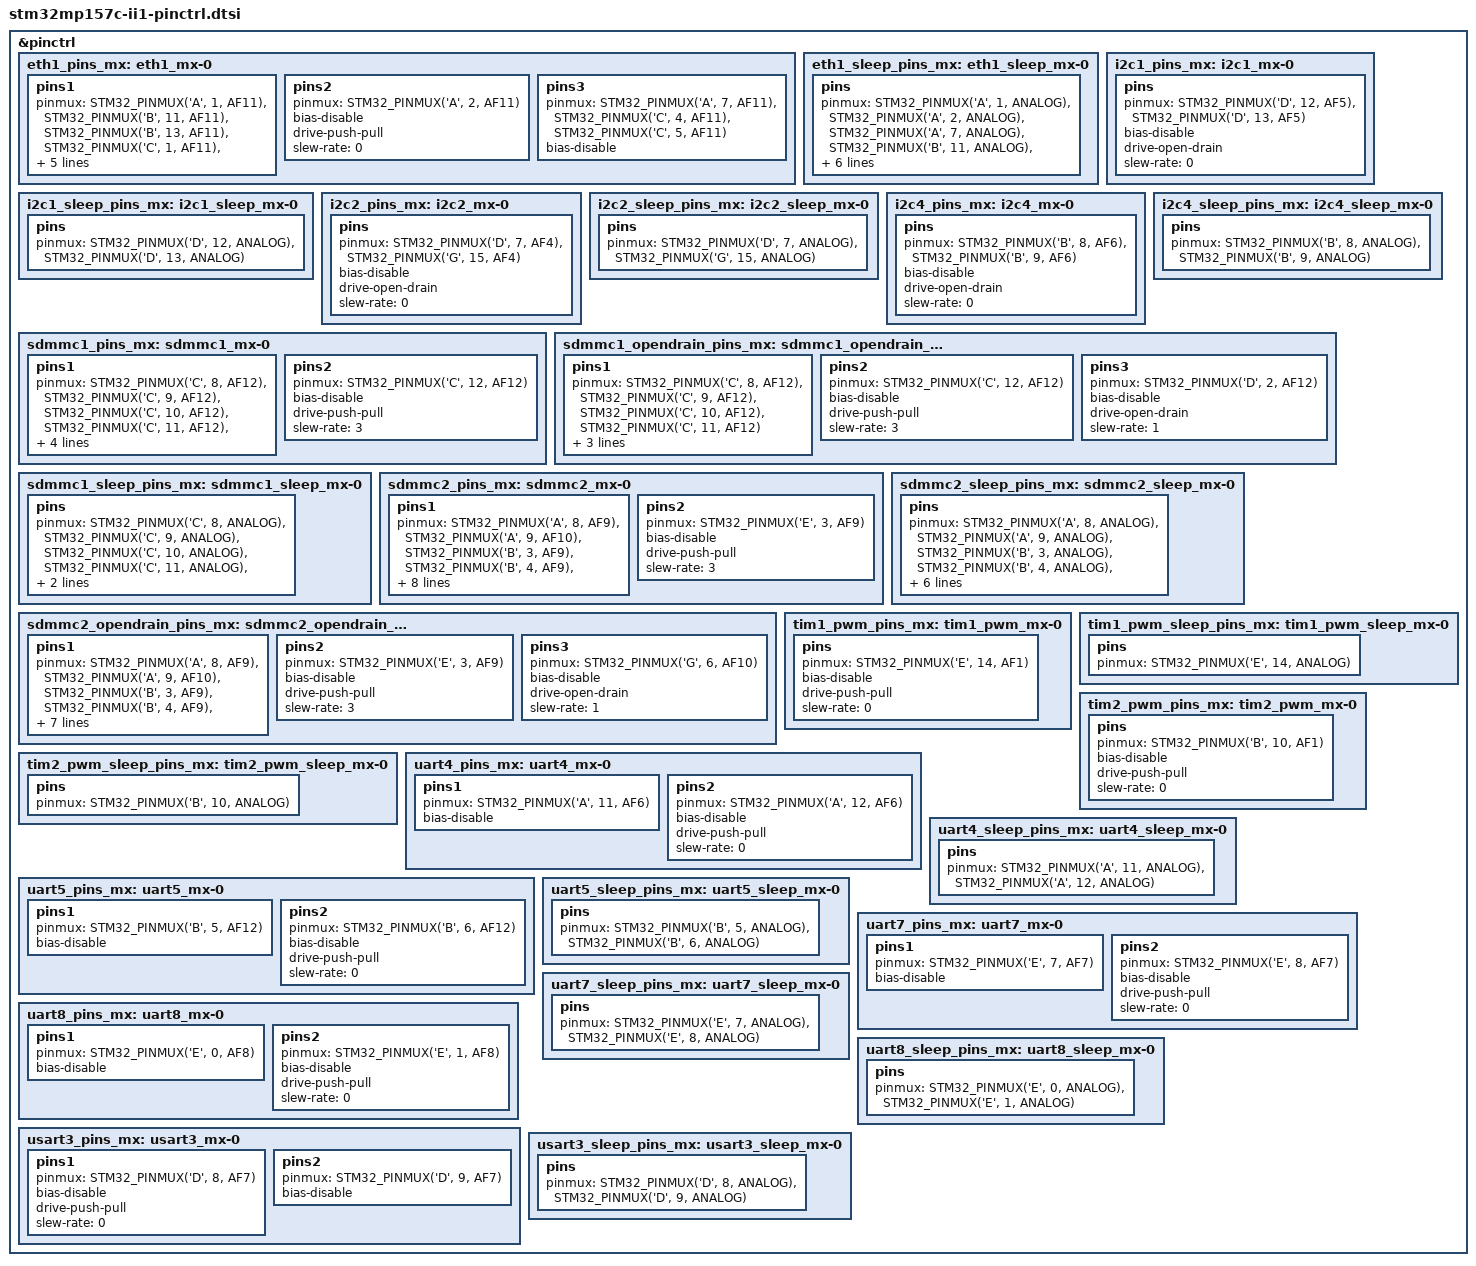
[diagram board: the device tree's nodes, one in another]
// SPDX-License-Identifier: (GPL-2.0+ OR BSD-3-Clause)
/*
 * Copyright (C) 2023  Braiins Systems s.r.o.
 *
 * This file is part of Braiins Open-Source Initiative (BOSI).
 *
 * BOSI is free software: you can redistribute it and/or modify
 * it under the terms of the GNU General Public License as published by
 * the Free Software Foundation, either version 3 of the License, or
 * (at your option) any later version.
 *
 * This program is distributed in the hope that it will be useful,
 * but WITHOUT ANY WARRANTY; without even the implied warranty of
 * MERCHANTABILITY or FITNESS FOR A PARTICULAR PURPOSE.  See the
 * GNU General Public License for more details.
 *
 * You should have received a copy of the GNU General Public License
 * along with this program.  If not, see <https://www.gnu.org/licenses/>.
 *
 * Please, keep in mind that we may also license BOSI or any part thereof
 * under a proprietary license. For more information on the terms and conditions
 * of such proprietary license or if you have any other questions, please
 * contact us at opensource@braiins.com.
 */

#include <dt-bindings/pinctrl/stm32-pinfunc.h>

&pinctrl {

	eth1_pins_mx: eth1_mx-0 {
		pins1 {
			pinmux = <STM32_PINMUX('A', 1, AF11)>, /* ETH1_REF_CLK */
					 <STM32_PINMUX('B', 11, AF11)>, /* ETH1_TX_EN */
					 <STM32_PINMUX('B', 13, AF11)>, /* ETH1_TXD1 */
					 <STM32_PINMUX('C', 1, AF11)>, /* ETH1_MDC */
					 <STM32_PINMUX('G', 8, AF2)>, /* ETH1_CLK */
					 <STM32_PINMUX('G', 13, AF11)>; /* ETH1_TXD0 */
			bias-disable;
			drive-push-pull;
			slew-rate = <1>;
		};
		pins2 {
			pinmux = <STM32_PINMUX('A', 2, AF11)>; /* ETH1_MDIO */
			bias-disable;
			drive-push-pull;
			slew-rate = <0>;
		};
		pins3 {
			pinmux = <STM32_PINMUX('A', 7, AF11)>, /* ETH1_CRS_DV */
					 <STM32_PINMUX('C', 4, AF11)>, /* ETH1_RXD0 */
					 <STM32_PINMUX('C', 5, AF11)>; /* ETH1_RXD1 */
			bias-disable;
		};
	};

	eth1_sleep_pins_mx: eth1_sleep_mx-0 {
		pins {
			pinmux = <STM32_PINMUX('A', 1, ANALOG)>, /* ETH1_REF_CLK */
					 <STM32_PINMUX('A', 2, ANALOG)>, /* ETH1_MDIO */
					 <STM32_PINMUX('A', 7, ANALOG)>, /* ETH1_CRS_DV */
					 <STM32_PINMUX('B', 11, ANALOG)>, /* ETH1_TX_EN */
					 <STM32_PINMUX('B', 13, ANALOG)>, /* ETH1_TXD1 */
					 <STM32_PINMUX('C', 1, ANALOG)>, /* ETH1_MDC */
					 <STM32_PINMUX('C', 4, ANALOG)>, /* ETH1_RXD0 */
					 <STM32_PINMUX('C', 5, ANALOG)>, /* ETH1_RXD1 */
					 <STM32_PINMUX('G', 8, ANALOG)>, /* ETH1_CLK */
					 <STM32_PINMUX('G', 13, ANALOG)>; /* ETH1_TXD0 */
		};
	};

	i2c1_pins_mx: i2c1_mx-0 {
		pins {
			pinmux = <STM32_PINMUX('D', 12, AF5)>, /* I2C1_SCL */
					 <STM32_PINMUX('D', 13, AF5)>; /* I2C1_SDA */
			bias-disable;
			drive-open-drain;
			slew-rate = <0>;
		};
	};

	i2c1_sleep_pins_mx: i2c1_sleep_mx-0 {
		pins {
			pinmux = <STM32_PINMUX('D', 12, ANALOG)>, /* I2C1_SCL */
					 <STM32_PINMUX('D', 13, ANALOG)>; /* I2C1_SDA */
		};
	};

	i2c2_pins_mx: i2c2_mx-0 {
		pins {
			pinmux = <STM32_PINMUX('D', 7, AF4)>, /* I2C2_SCL */
					 <STM32_PINMUX('G', 15, AF4)>; /* I2C2_SDA */
			bias-disable;
			drive-open-drain;
			slew-rate = <0>;
		};
	};

	i2c2_sleep_pins_mx: i2c2_sleep_mx-0 {
		pins {
			pinmux = <STM32_PINMUX('D', 7, ANALOG)>, /* I2C2_SCL */
					 <STM32_PINMUX('G', 15, ANALOG)>; /* I2C2_SDA */
		};
	};

	i2c4_pins_mx: i2c4_mx-0 {
		pins {
			pinmux = <STM32_PINMUX('B', 8, AF6)>, /* I2C4_SCL */
					 <STM32_PINMUX('B', 9, AF6)>; /* I2C4_SDA */
			bias-disable;
			drive-open-drain;
			slew-rate = <0>;
		};
	};

	i2c4_sleep_pins_mx: i2c4_sleep_mx-0 {
		pins {
			pinmux = <STM32_PINMUX('B', 8, ANALOG)>, /* I2C4_SCL */
					 <STM32_PINMUX('B', 9, ANALOG)>; /* I2C4_SDA */
		};
	};

	sdmmc1_pins_mx: sdmmc1_mx-0 {
		pins1 {
			pinmux = <STM32_PINMUX('C', 8, AF12)>, /* SDMMC1_D0 */
					 <STM32_PINMUX('C', 9, AF12)>, /* SDMMC1_D1 */
					 <STM32_PINMUX('C', 10, AF12)>, /* SDMMC1_D2 */
					 <STM32_PINMUX('C', 11, AF12)>, /* SDMMC1_D3 */
					 <STM32_PINMUX('D', 2, AF12)>; /* SDMMC1_CMD */
			bias-disable;
			drive-push-pull;
			slew-rate = <1>;
		};
		pins2 {
			pinmux = <STM32_PINMUX('C', 12, AF12)>; /* SDMMC1_CK */
			bias-disable;
			drive-push-pull;
			slew-rate = <3>;
		};
	};

	sdmmc1_opendrain_pins_mx: sdmmc1_opendrain_mx-0 {
		pins1 {
			pinmux = <STM32_PINMUX('C', 8, AF12)>, /* SDMMC1_D0 */
					 <STM32_PINMUX('C', 9, AF12)>, /* SDMMC1_D1 */
					 <STM32_PINMUX('C', 10, AF12)>, /* SDMMC1_D2 */
					 <STM32_PINMUX('C', 11, AF12)>; /* SDMMC1_D3 */
			bias-disable;
			drive-push-pull;
			slew-rate = <1>;
		};
		pins2 {
			pinmux = <STM32_PINMUX('C', 12, AF12)>; /* SDMMC1_CK */
			bias-disable;
			drive-push-pull;
			slew-rate = <3>;
		};
		pins3 {
			pinmux = <STM32_PINMUX('D', 2, AF12)>; /* SDMMC1_CMD */
			bias-disable;
			drive-open-drain;
			slew-rate = <1>;
		};
	};

	sdmmc1_sleep_pins_mx: sdmmc1_sleep_mx-0 {
		pins {
			pinmux = <STM32_PINMUX('C', 8, ANALOG)>, /* SDMMC1_D0 */
					 <STM32_PINMUX('C', 9, ANALOG)>, /* SDMMC1_D1 */
					 <STM32_PINMUX('C', 10, ANALOG)>, /* SDMMC1_D2 */
					 <STM32_PINMUX('C', 11, ANALOG)>, /* SDMMC1_D3 */
					 <STM32_PINMUX('C', 12, ANALOG)>, /* SDMMC1_CK */
					 <STM32_PINMUX('D', 2, ANALOG)>; /* SDMMC1_CMD */
		};
	};

	sdmmc2_pins_mx: sdmmc2_mx-0 {
		pins1 {
			pinmux = <STM32_PINMUX('A', 8, AF9)>, /* SDMMC2_D4 */
					 <STM32_PINMUX('A', 9, AF10)>, /* SDMMC2_D5 */
					 <STM32_PINMUX('B', 3, AF9)>, /* SDMMC2_D2 */
					 <STM32_PINMUX('B', 4, AF9)>, /* SDMMC2_D3 */
					 <STM32_PINMUX('B', 14, AF9)>, /* SDMMC2_D0 */
					 <STM32_PINMUX('B', 15, AF9)>, /* SDMMC2_D1 */
					 <STM32_PINMUX('D', 3, AF9)>, /* SDMMC2_D7 */
					 <STM32_PINMUX('E', 5, AF9)>, /* SDMMC2_D6 */
					 <STM32_PINMUX('G', 6, AF10)>; /* SDMMC2_CMD */
			bias-disable;
			drive-push-pull;
			slew-rate = <1>;
		};
		pins2 {
			pinmux = <STM32_PINMUX('E', 3, AF9)>; /* SDMMC2_CK */
			bias-disable;
			drive-push-pull;
			slew-rate = <3>;
		};
	};

	sdmmc2_opendrain_pins_mx: sdmmc2_opendrain_mx-0 {
		pins1 {
			pinmux = <STM32_PINMUX('A', 8, AF9)>, /* SDMMC2_D4 */
					 <STM32_PINMUX('A', 9, AF10)>, /* SDMMC2_D5 */
					 <STM32_PINMUX('B', 3, AF9)>, /* SDMMC2_D2 */
					 <STM32_PINMUX('B', 4, AF9)>, /* SDMMC2_D3 */
					 <STM32_PINMUX('B', 14, AF9)>, /* SDMMC2_D0 */
					 <STM32_PINMUX('B', 15, AF9)>, /* SDMMC2_D1 */
					 <STM32_PINMUX('D', 3, AF9)>, /* SDMMC2_D7 */
					 <STM32_PINMUX('E', 5, AF9)>; /* SDMMC2_D6 */
			bias-disable;
			drive-push-pull;
			slew-rate = <1>;
		};
		pins2 {
			pinmux = <STM32_PINMUX('E', 3, AF9)>; /* SDMMC2_CK */
			bias-disable;
			drive-push-pull;
			slew-rate = <3>;
		};
		pins3 {
			pinmux = <STM32_PINMUX('G', 6, AF10)>; /* SDMMC2_CMD */
			bias-disable;
			drive-open-drain;
			slew-rate = <1>;
		};
	};

	sdmmc2_sleep_pins_mx: sdmmc2_sleep_mx-0 {
		pins {
			pinmux = <STM32_PINMUX('A', 8, ANALOG)>, /* SDMMC2_D4 */
					 <STM32_PINMUX('A', 9, ANALOG)>, /* SDMMC2_D5 */
					 <STM32_PINMUX('B', 3, ANALOG)>, /* SDMMC2_D2 */
					 <STM32_PINMUX('B', 4, ANALOG)>, /* SDMMC2_D3 */
					 <STM32_PINMUX('B', 14, ANALOG)>, /* SDMMC2_D0 */
					 <STM32_PINMUX('B', 15, ANALOG)>, /* SDMMC2_D1 */
					 <STM32_PINMUX('D', 3, ANALOG)>, /* SDMMC2_D7 */
					 <STM32_PINMUX('E', 3, ANALOG)>, /* SDMMC2_CK */
					 <STM32_PINMUX('E', 5, ANALOG)>, /* SDMMC2_D6 */
					 <STM32_PINMUX('G', 6, ANALOG)>; /* SDMMC2_CMD */
		};
	};

	tim1_pwm_pins_mx: tim1_pwm_mx-0 {
		pins {
			pinmux = <STM32_PINMUX('E', 14, AF1)>; /* TIM1_CH4 */
			bias-disable;
			drive-push-pull;
			slew-rate = <0>;
		};
	};

	tim1_pwm_sleep_pins_mx: tim1_pwm_sleep_mx-0 {
		pins {
			pinmux = <STM32_PINMUX('E', 14, ANALOG)>; /* TIM1_CH4 */
		};
	};

	tim2_pwm_pins_mx: tim2_pwm_mx-0 {
		pins {
			pinmux = <STM32_PINMUX('B', 10, AF1)>; /* TIM2_CH3 */
			bias-disable;
			drive-push-pull;
			slew-rate = <0>;
		};
	};

	tim2_pwm_sleep_pins_mx: tim2_pwm_sleep_mx-0 {
		pins {
			pinmux = <STM32_PINMUX('B', 10, ANALOG)>; /* TIM2_CH3 */
		};
	};

	uart4_pins_mx: uart4_mx-0 {
		pins1 {
			pinmux = <STM32_PINMUX('A', 11, AF6)>; /* UART4_RX */
			bias-disable;
		};
		pins2 {
			pinmux = <STM32_PINMUX('A', 12, AF6)>; /* UART4_TX */
			bias-disable;
			drive-push-pull;
			slew-rate = <0>;
		};
	};

	uart4_sleep_pins_mx: uart4_sleep_mx-0 {
		pins {
			pinmux = <STM32_PINMUX('A', 11, ANALOG)>, /* UART4_RX */
					 <STM32_PINMUX('A', 12, ANALOG)>; /* UART4_TX */
		};
	};

	uart5_pins_mx: uart5_mx-0 {
		pins1 {
			pinmux = <STM32_PINMUX('B', 5, AF12)>; /* UART5_RX */
			bias-disable;
		};
		pins2 {
			pinmux = <STM32_PINMUX('B', 6, AF12)>; /* UART5_TX */
			bias-disable;
			drive-push-pull;
			slew-rate = <0>;
		};
	};

	uart5_sleep_pins_mx: uart5_sleep_mx-0 {
		pins {
			pinmux = <STM32_PINMUX('B', 5, ANALOG)>, /* UART5_RX */
					 <STM32_PINMUX('B', 6, ANALOG)>; /* UART5_TX */
		};
	};

	uart7_pins_mx: uart7_mx-0 {
		pins1 {
			pinmux = <STM32_PINMUX('E', 7, AF7)>; /* UART7_RX */
			bias-disable;
		};
		pins2 {
			pinmux = <STM32_PINMUX('E', 8, AF7)>; /* UART7_TX */
			bias-disable;
			drive-push-pull;
			slew-rate = <0>;
		};
	};

	uart7_sleep_pins_mx: uart7_sleep_mx-0 {
		pins {
			pinmux = <STM32_PINMUX('E', 7, ANALOG)>, /* UART7_RX */
					 <STM32_PINMUX('E', 8, ANALOG)>; /* UART7_TX */
		};
	};

	uart8_pins_mx: uart8_mx-0 {
		pins1 {
			pinmux = <STM32_PINMUX('E', 0, AF8)>; /* UART8_RX */
			bias-disable;
		};
		pins2 {
			pinmux = <STM32_PINMUX('E', 1, AF8)>; /* UART8_TX */
			bias-disable;
			drive-push-pull;
			slew-rate = <0>;
		};
	};

	uart8_sleep_pins_mx: uart8_sleep_mx-0 {
		pins {
			pinmux = <STM32_PINMUX('E', 0, ANALOG)>, /* UART8_RX */
					 <STM32_PINMUX('E', 1, ANALOG)>; /* UART8_TX */
		};
	};

	usart3_pins_mx: usart3_mx-0 {
		pins1 {
			pinmux = <STM32_PINMUX('D', 8, AF7)>; /* USART3_TX */
			bias-disable;
			drive-push-pull;
			slew-rate = <0>;
		};
		pins2 {
			pinmux = <STM32_PINMUX('D', 9, AF7)>; /* USART3_RX */
			bias-disable;
		};
	};

	usart3_sleep_pins_mx: usart3_sleep_mx-0 {
		pins {
			pinmux = <STM32_PINMUX('D', 8, ANALOG)>, /* USART3_TX */
					 <STM32_PINMUX('D', 9, ANALOG)>; /* USART3_RX */
		};
	};
};
